# pse84_a0 register map
Vendor: Infineon Technologies; Series: PSE84_A0; File version: 1.0
CPU: CM33 r0p1, little endian, MPU, FPU, VTOR, 3 interrupt priority bits
Registers are 32-bit, read-write, reset 0x0 unless marked. A register's access mark holds for its fields unless they carry their own. Offsets are from the block's base; [hi:lo] are bit positions; lines under a group give offsets from that group; {n}, {i} and the like mark numbered series.

## INFRA — LPPASS infrastructure
Base 0x42EE0000
0x04 CLOCK_PTC_LP_DIV — Low Power Clock divider for PTC (only accessible if ACTRLR.STATUS.MODE=0)
  [9:0] DIV_VAL — Actual divide value is DIV_VAL+1. The root clock for this divider is the LPPASS LPOSC (4.096MHz nominal). This field is only used if the PTC is enabled (AC.PTC_CMP0(1)_EN=1) and the Autonomous Controller is configured for LP mode (ACTRLR.STATUS.MODE=LP).
{0x8+4i} CLOCK_DAC_LP_DIV[{i}] (i=0..1) reset 0x3 — Low Power Clock divider for DAC (only accessible if ACTRLR.STATUS.MODE=0)
  [9:0] DIV_VAL — Actual divide value is DIV_VAL+1. The root clock for this divider is the LPPASS LPOSC (4.096MHz nominal). This field is only used if the DAC is enabled (AC.DAC0(1)_EN=1) and the Autonomous Controller is configured for LP mode (ACTRLR.STATUS.MODE=LP).
0x14 CLOCK_PRIO_HS_DIV reset 0x13 — Clock enable for IP priority enabler (only accessible if ACTRLR.STATUS.MODE=0)
  [9:0] DIV_VAL — Actual divide value is DIV_VAL+1. The DIV value must be set to ensure that the corresponding clock rate is set to 4MHz. (The high speed system clock frequency is expected to be set to 80MHz, therby a defult DIV_VAL of 19 yields a 4MHz PRIO_HS clock).
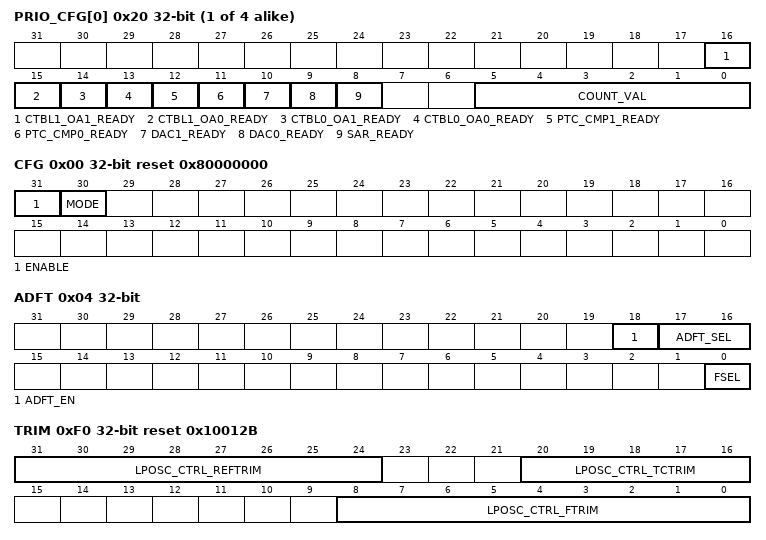
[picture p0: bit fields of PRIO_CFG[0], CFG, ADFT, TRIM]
{0x20+4i} PRIO_CFG[{i}] (i=0..3) — Sub IP Block IP priority enabler configuration (only accessible if ACTRLR.STATUS.MODE=0)
  [16] CTBL1_OA1_READY — CTBL1 opamp1 ready
  [15] CTBL1_OA0_READY — CTBL1 opamp0 ready
  [14] CTBL0_OA1_READY — CTBL0 opamp1 ready
  [13] CTBL0_OA0_READY — CTBL0 opamp0 ready
  [12] PTC_CMP1_READY — PTC comparator 1 ready
  [11] PTC_CMP0_READY — PTC comparator 0 ready
  [10] DAC1_READY
  [9] DAC0_READY
  [8] SAR_READY
  [5:0] COUNT_VAL — Actual count value is COUNT_VAL+1. This field determines the time delay between the Autonomous Controller (AC) setting the particular block enable bit and the corresponding assertion of the ready status bit. The delay time is based on a 4MHz clock (the corresponding delay time is 250ns*COUNT_VAL+1 (Delay time ranges from 250ns to 16us)). If delay times greater than 16us are required, then multiple PRIO_CFG states must be programmed to generate a cascade of delays (4 PRIO_CFG state*16us=64us maximum possible delay).
0x100 LPOSC group — LPOSC configuration (only accessible if ACTRLR.STATUS.MODE=0)
  0x00 CFG reset 0x80000000 — Low Power Oscillator configuration register
    [31] ENABLE — Master enable for LPOSC oscillator. This bit must be high at all times for all functions to work properly. Hardware will automatically disable the LPOSC during HIBERNATE and XRES.
    [30] MODE — LPOSC functionality
      0=ALWAYS_ON (LPOSC always ON); 1=DUTY_CYCLED (LPOSC duty cycled based on AC Wakeup Signal)
  0x04 ADFT — Retention, Hidden
    [18] ADFT_EN — Enable ADFT selection for LPOSC.
    [17:16] ADFT_SEL
    [0] FSEL — LPOSC Frequency Select 0: 4MHz 1: 2MHz
  0xF0 TRIM reset 0x10012B — LPOSC Trim Register
    [31:24] LPOSC_CTRL_REFTRIM — LPOSC reference trims
    [20:16] LPOSC_CTRL_TCTRIM — LPOSC temperature compensation trim
    [8:0] LPOSC_CTRL_FTRIM — LPOSC frequency trim
0x200 AREF group — AREF configuration (only accessible if ACTRLR.STATUS.MODE=0)
  0x00 CTRL — AREF control
    [8] VREF_SEL — bandgap voltage select control
      0=LOCAL (Use locally generated Vref); 1=EXTERNAL (Use externally supplied Vref (aref_ext_vref))
  0xD0 VREF_TRIM0 — VREF Trim bits
    [4:0] VREF_ABS_TRIM — bandgap absolute voltage output trim (in signed magnitude format) 0x00 : No Voltage Trim Adjustment 0x1F : Maximum Positive Trim Adjustment (+20mV)
  0xD4 VREF_TRIM1 — VREF Trim bits
    [5:0] VREF_TEMPCO_TRIM — bandgap voltage temperature correction trim 0x00 : Minimum temperature correction (smallest PTAT voltage) 0x3F : Maximum temperature correction (largest PTAT voltage)
  0xD8 VREF_TRIM2 — VREF Trim bits
    [3:0] VREF_IPTAT2_ICTAT_TRIM
  0xDC VREF_TRIM3 — VREF Trim bits
    [4:0] VREF_IPTAT2_DAC_TRIM
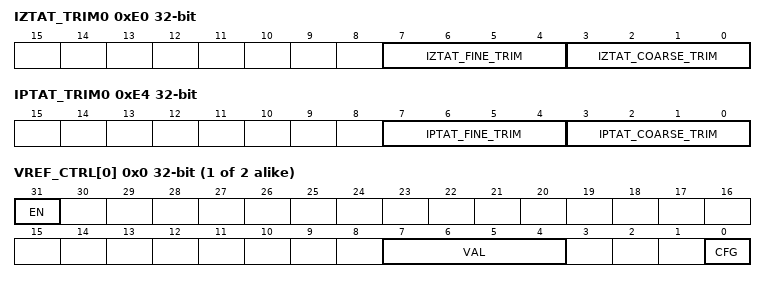
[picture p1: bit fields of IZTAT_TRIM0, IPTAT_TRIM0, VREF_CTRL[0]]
  0xE0 IZTAT_TRIM0 — IZTAT Trim bits
    [7:4] IZTAT_FINE_TRIM — IZTAT temperature correction trim (RMB) 0x00 : No IZTAT temperature correction 0xFF : Maximum IZTAT temperature correction As this is a Risk Mitigation Register, it should be loaded with 0x08.
    [3:0] IZTAT_COARSE_TRIM
  0xE4 IPTAT_TRIM0 — IPTAT Trim bits
    [7:4] IPTAT_FINE_TRIM — IPTAT fine trim 0x0 : Minimum CTMB IPTAT Current (~875nA) 0xF : Maximum CTMB IPTAT Current (~1.1uA)
    [3:0] IPTAT_COARSE_TRIM — IPTAT coarse trim 0x0 : Minimum IPTAT current (~150nA at room) 0xF : Maximum IPTAT current (~350nA at room)
  0xE8 IPTAT_TRIM1 — IPTAT Trim bits
    [4:0] IPTAT_DAC_TRIM — IPTAT DAC trim 0x0 : Minimum IPTAT current (~150nA at room) 0xF : Maximum IPTAT current (~350nA at room)
  0xEC ICTAT_TRIM0 — ICTAT Trim bits
    [3:0] RSVD
  0xF0 ICTAT_TRIM1 — ICTAT Trim bits
    [4:0] ICTAT_COARSE_TRIM — ICTAT coarse trim 0x0 : Minimum IPTAT current (~150nA at room) 0xF : Maximum IPTAT current (~350nA at room)
  0xF4 ICTAT_TRIM2 — ICTAT Trim bits
    [2:0] ICTAT_FINE_TRIM — ICTAT fine trim 0x0 : Minimum CTMB IPTAT Current (~875nA) 0xF : Maximum CTMB IPTAT Current (~1.1uA)
0x300 PRB group — PRB configuration (only accessible if ACTRLR.STATUS.MODE=0)
  {0x0+4j} VREF_CTRL[{j}] (j=0..1) — PRB VREF Control
    [31] EN — PRB VREF enable control
      0=DISABLED (N/A); 1=ENABLED (N/A)
    [7:4] VAL — TAP location for PRB VREF
      {v}=TAP_{v} (N/A) (v=0..15)
    [0] CFG — PRB VREF reference configuration
      0=VBG (reference derived from VBG); 1=VDDA (reference derived from VDDA)
0x400 TIMER group — Wakeup Timer configuration (only accessible if ACTRLR.STATUS.MODE=0)
  0x00 CTRL — Timer trigger control register
    [31] ENABLED — 0=disabled, 1=enabled This timer (downcounter) is used by the Autonomous Controller (AC) as a wakeup source ( Autonomous Controller Action (ACT) = WAIT_FOR and Condition (COND) = TIMER_DONE_WAKE). Even if CTRL.ENABLED is set, the Timer is held in Reset until the Autonomous Controller is running (ACTRLR.STATUS.STATUS= RUNNING). The Timer automatically resets whenenever the Autonomous Controller transitions between HS and LP modes, is paused, or disabled. The timer will generate a wakeup signal to the AC whenever it reaches Terminal Count (0).
  0x04 CFG — Timer trigger configuration register
    [1:0] CLOCK_SEL — Select Clock source of the Timer
      0=CLK_LPOSC (Timer clocked from CLK_LPOSC (nominally 4.096MHz)); 1=CLK_LF (Timer clocked from CLK_LF (nominally 32kHz)); 2=TBD_0 (N/A); 3=TBD_1 (N/A)
  0x08 PERIOD — Timer trigger period register
    [15:0] PER_VAL — Actual timer period is PER_VAL+1 (1 to 65536).
